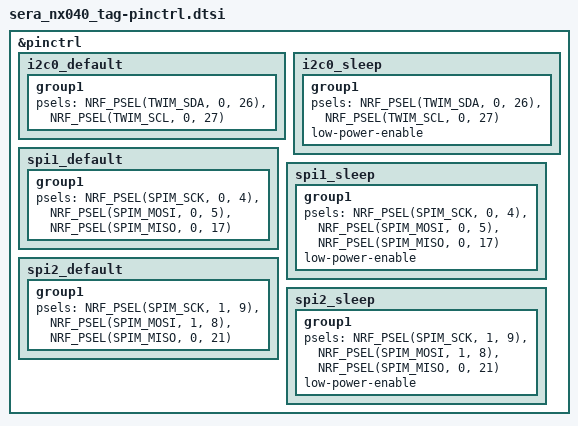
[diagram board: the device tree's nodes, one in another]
/*
 * Copyright (c) 2024 Nordic Semiconductor
 * SPDX-License-Identifier: Apache-2.0
 */

&pinctrl {
	i2c0_default: i2c0_default {
		group1 {
			psels = <NRF_PSEL(TWIM_SDA, 0, 26)>,
				<NRF_PSEL(TWIM_SCL, 0, 27)>;
		};
	};

	i2c0_sleep: i2c0_sleep {
		group1 {
			psels = <NRF_PSEL(TWIM_SDA, 0, 26)>,
				<NRF_PSEL(TWIM_SCL, 0, 27)>;
			low-power-enable;
		};
	};

	spi1_default: spi1_default {
		group1 {
			psels = <NRF_PSEL(SPIM_SCK, 0, 4)>,
				<NRF_PSEL(SPIM_MOSI, 0, 5)>,
				<NRF_PSEL(SPIM_MISO, 0, 17)>;
		};
	};

	spi1_sleep: spi1_sleep {
		group1 {
			psels = <NRF_PSEL(SPIM_SCK, 0, 4)>,
				<NRF_PSEL(SPIM_MOSI, 0, 5)>,
				<NRF_PSEL(SPIM_MISO, 0, 17)>;
			low-power-enable;
		};
	};

	spi2_default: spi2_default {
		group1 {
			psels = <NRF_PSEL(SPIM_SCK, 1, 9)>,
				<NRF_PSEL(SPIM_MOSI, 1, 8)>,
				<NRF_PSEL(SPIM_MISO, 0, 21)>;
		};
	};

	spi2_sleep: spi2_sleep {
		group1 {
			psels = <NRF_PSEL(SPIM_SCK, 1, 9)>,
				<NRF_PSEL(SPIM_MOSI, 1, 8)>,
				<NRF_PSEL(SPIM_MISO, 0, 21)>;
			low-power-enable;
		};
	};
};
